# PIC32MX440F128H register map
Vendor: Microchip
Architecture 32xxxx. Special function registers and configuration words.
Registers are 32-bit, read-write, reset 0x0 unless marked. A register's access mark holds for its fields unless they carry their own. Addresses are absolute, and some are shared; only a register's first bit layout is shown; lines under a group give offsets from that group; [hi:lo] are bit positions; {n}, {i} and the like mark numbered series; 'fields as' and 'values as' point back to an identical list; <NAME> marks a mode.

## Further device data
pins=1: RE5/PMD5; 2: RE6/PMD6; 3: RE7/PMD7; 4: RG6/CN8/PMA5/SCK2; 5: RG7/CN9/PMA4/SDI2; 6: RG8/CN10/PMA3/SDO2; 7: MCLR; 8: RG9/CN11/PMA2/SS2; 9: VSS; 10: VDD; 11: RB5/CN7/VBUSON/C1IN+/AN5; 12: RB4/CN6/C1IN-/AN4; 13: RB3/CN5/C2IN+/AN3; 14: RB2/CN4/C2IN-/AN2; 15: RB1/CN3/VREF-/AN1/PGEC1; 16: RB0/CN2/PMA6/VREF+/AN0/PGED1; 17: RB6/OCFA/AN6/PGEC2; 18: RB7/AN7/PGED2; 19: AVDD; 20: AVSS; 21: RB8/C1OUT/U2CTS/AN8; 22: RB9/PMA7/C2OUT/AN9; 23: RB10/PMA13/CVREFOUT/AN10/TMS; 24: RB11/PMA12/AN11/TDO; 25: VSS; 26: VDD; 27: RB12/PMA11/AN12/TCK; 28: RB13/PMA10/AN13/TDI; 29: RB14/PMA1/PMALH/U2RTS/AN14; 30: RB15/CN12/PMA0/PMALL/OCFB/AN15; 31: RF4/CN17/PMA9/U2RX/SDA2; 32: RF5/CN18/PMA8/U2TX/SCL2; 33: RF3/USBID; 34: VBUS; 35: VUSB3V3; 36: RG3/D-; 37: RG2/D+; 38: VDD; 39: RC12/CLKI/OSC1; 40: RC15/CLKO/OSC2; 41: VSS; 42: RD8/INT1/IC1/RTCC; 43: RD9/INT2/IC2/SDA1/U1CTS; 44: RD10/INT3/PMA15/PMCS2/IC3/SCL1; 45: RD11/INT4/PMA14/PMCS1/IC4; 46: RD0/INT0/OC1; 47: RC13/CN1/SOSCI; 48: RC14/CN0/T1CK/SOSCO; 49: RD1/OC2/U1RTS; 50: RD2/OC3/U1RX; 51: RD3/OC4/U1TX; 52: RD4/CN13/PMWR/IC5/OC5; 53: RD5/CN14/PMRD; 54: RD6/CN15; 55: RD7/CN16; 56: VCORE/VCAP; 57: ENVREG; 58: RF0; 59: RF1; 60: RE0/PMD0; 61: RE1/PMD1; 62: RE2/PMD2; 63: RE3/PMD3; 64: RE4/PMD4, interrupts=0 CORE_TIMER — Core Timer; 1 CORE_SOFTWARE_0 — Core Software 0; 2 CORE_SOFTWARE_1 — Core Software 1; 3 EXTERNAL_0 — Ext INT 0; 7 EXTERNAL_1 — Ext INT 1; 11 EXTERNAL_2 — Ext INT 2; 15 EXTERNAL_3 — Ext INT 3; 19 EXTERNAL_4 — Ext INT 4; 4 TIMER_1 — Timer1; 8 TIMER_2 — Timer2; 12 TIMER_3 — Timer3; 16 TIMER_4 — Timer4; 20 TIMER_5 — Timer5; 26 CHANGE_NOTICE — Change Notice; 5 INPUT_CAPTURE_1 — Input Capture 1; 9 INPUT_CAPTURE_2 — Input Capture 2; 13 INPUT_CAPTURE_3 — Input Capture 3; 17 INPUT_CAPTURE_4 — Input Capture 4; 21 INPUT_CAPTURE_5 — Input Capture 5; 6 OUTPUT_COMPARE_1 — Output Compare 1; 10 OUTPUT_COMPARE_2 — Output Compare 2; 14 OUTPUT_COMPARE_3 — Output Compare 3; 18 OUTPUT_COMPARE_4 — Output Compare 4; 22 OUTPUT_COMPARE_5 — Output Compare 5; 24 UART_1 — UART 1; 25 I2C_1 — I2C 1; 31 SPI_2 — SPI 2; 32 UART_2 — UART 2; 33 I2C_2 — I2C 2; 29 COMPARATOR_1 — Comparator 1; 30 COMPARATOR_2 — Comparator 2; 27 ADC — ADC; 28 PMP — PMP; 34 FAIL_SAFE_MONITOR — Fail Safe Clock Monitor; 35 RTCC — Real Time Clock Calendar; 44 FCE — Flash Control Event; 36 DMA_0 — DMA Channel 0; 37 DMA_1 — DMA Channel 1; 38 DMA_2 — DMA Channel 2; 39 DMA_3 — DMA Channel 3; 45 USB_1 — USB Module 1

## WDT
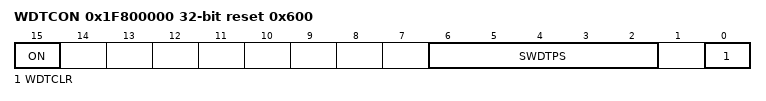
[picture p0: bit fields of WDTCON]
0x1F800000 WDTCON reset 0x600
  [15] ON, [6:2] SWDTPS ro, [0] WDTCLR
